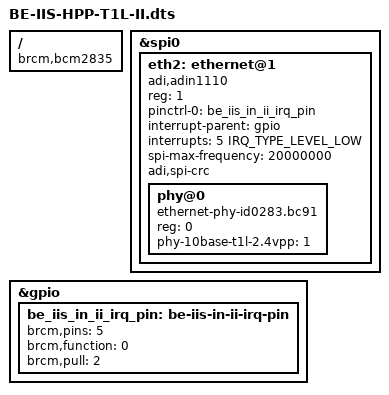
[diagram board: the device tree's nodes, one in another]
// Raspberry Pi DT overlay: Analog Devices ADIN1110 on SPI0 (CE1)
// IRQ: BCM GPIO5 (falling edge)
// CE1: BCM GPIO7 (falling edge)
// SPI must be enabled in config.txt:
//     dtparam=spi=on
//
// Supported Raspberry Pi models (SPI0-based):
//   - Raspberry Pi Zero 2 W (64Bit)
//   - Raspberry Pi 4 (64Bit)
//   - Raspberry Pi 5 (64Bit)
//
// Notes:
//   - Uses SPI0 + CE1
//   - Uses BCM GPIO numbering
//   - Works across bcm2835 / bcm2711 / bcm2712


/dts-v1/;
/plugin/;

#include <dt-bindings/interrupt-controller/irq.h>
#include <dt-bindings/gpio/gpio.h>

/ {
	/*
	 * RPi firmware doesn’t really *use* this for overlays, but keeping it sane helps.
	 * Works across Pi Zero / 2 / 3 / 4 / 5
	 */
	compatible = "brcm,bcm2835", "brcm,bcm2711", "brcm,bcm2712";

	fragment@0 {
		target = <&spi0>;
		__overlay__ {
			/* avoid dtc warnings */
			#address-cells = <1>;
			#size-cells = <0>;
			status = "okay";

			/*
			 * LAN865x on SPI0, chip select 1 (CE1)
			 * Interrupt on GPIO5, falling edge
			 */
			eth2: ethernet@1 {
				compatible = "adi,adin1110";
				reg = <1>; /* CE1 */
				
                                pinctrl-names = "default";
                                pinctrl-0 = <&be_iis_in_ii_irq_pin>;
				
				interrupt-parent = <&gpio>;
				interrupts = <5 IRQ_TYPE_LEVEL_LOW>;

				/* optional: set a fixed MAC (better: let it be set by userspace)
				mac-address = [ 02 00 00 00 00 02 ]; */

				/* LAN865x TC6 SPI clock; start conservative if unsure */
				spi-max-frequency = <20000000>;
				
				/* optional SPI CRC checking */
				adi,spi-crc;


				#address-cells = <1>;
				#size-cells = <0>;
				status = "okay";
				phy@0 {
					compatible = "ethernet-phy-id0283.bc91";
					reg = <0>;

					/* 10BASE-T1L amplitude selection */
					phy-10base-t1l-2.4vpp = <1>;
				};
			};
		};
	};

/* GPIO5 as input, pull-up (IRQ pin) */
fragment@2 {
    target = <&gpio>;
    __overlay__ {
        be_iis_in_ii_irq_pin: be-iis-in-ii-irq-pin {
            brcm,pins = <5>;
            brcm,function = <0>;
            brcm,pull = <2>;
        };
    };
};


	__overrides__ {
		int_pin = <&eth2>, "interrupts:0";
		speed   = <&eth2>, "spi-max-frequency:0";
		cs      = <&eth2>, "reg:0";
	};
};


/*
 * Brechel Electronic
 * Industrial Interface Systems
 *
 * Product: BE-IIS-HPP-CAN-FD-SIC
 *
 * Website:
 * https://www.be-iis.eu
 *
 * Digi-Key:
 * https://www.digikey.de/en/products/detail/brechel-electronic-industrial-interface-systems-be-iis/BE-IIS-HPP-T1L/29436903
 */
